AUTOSAR XML (schema 4-2-1)
package /ECUCompositionTypes
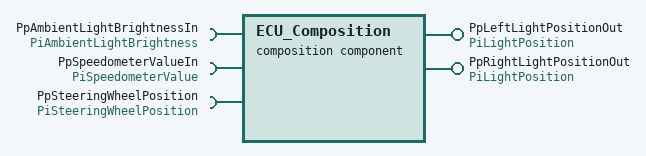
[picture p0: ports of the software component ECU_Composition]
  composition sw component type ECU_Composition
    provide port PpLeftLightPositionOut: provided-com-specs=[data-element=DeLightLength, {data-element=DeLightPosition, init-value=0}], provided-interface=PiLightPosition
    provide port PpRightLightPositionOut: provided-com-specs=[data-element=DeLightLength, {data-element=DeLightPosition, init-value=0}], provided-interface=PiLightPosition
    require port PpAmbientLightBrightnessIn: nonqueued-receiver-com-spec{data-element=DeAmbientLightBrightness, filter=data-filter-type=ALWAYS, init-value=constant-reference=CDarkLight}, required-interface=PiAmbientLightBrightness
    require port PpSpeedometerValueIn: nonqueued-receiver-com-spec{data-element=DeSpeedometerValue, filter=data-filter-type=ALWAYS, init-value=constant-reference=CInitSpeed}, required-interface=PiSpeedometerValue
    require port PpSteeringWheelPosition: nonqueued-receiver-com-spec{data-element=DeSteeringWheelPosition, filter=data-filter-type=ALWAYS, init-value=constant-reference=CSteeringWheelInitPosition}, required-interface=PiSteeringWheelPosition
    component CpCoApplication: type=CtCoApplication
    delegate CpCoApplication.PpAmbientLightBrightnessIn <-> outer port PpAmbientLightBrightnessIn
    delegate CpCoApplication.PpLeftLightPositionOut <-> outer port PpLeftLightPositionOut
    delegate CpCoApplication.PpRightLightPositionOut <-> outer port PpRightLightPositionOut
    delegate CpCoApplication.PpSpeedometerValueIn <-> outer port PpSpeedometerValueIn
    delegate CpCoApplication.PpSteeringWheelPosition <-> outer port PpSteeringWheelPosition
package /EndToEndProtections
  end to end protection set EndToEndConnections
package /VehicleProject
  system System: category=SYSTEM_EXTRACT
    system mapping System_MPPNG
      data-mappings:
        data-element=ECU_Composition.PpLeftLightPositionOut.DeLightPosition, system-signal=sig_LeftHAngle
        data-element=ECU_Composition.PpAmbientLightBrightnessIn.DeAmbientLightBrightness, system-signal=sig_AmbientLightBrightness
        data-element=ECU_Composition.PpSteeringWheelPosition.DeSteeringWheelPosition, system-signal=sig_SteeringWheelPosition
        data-element=ECU_Composition.PpLeftLightPositionOut.DeLightLength, system-signal=sig_LeftLightLength
        data-element=ECU_Composition.PpRightLightPositionOut.DeLightPosition, system-signal=sig_RightHAngle
        data-element=ECU_Composition.PpSpeedometerValueIn.DeSpeedometerValue, system-signal=sig_CurrentSpeedSlider
        data-element=ECU_Composition.PpRightLightPositionOut.DeLightLength, system-signal=sig_RightLightLength
    root-software-compositions:
      root sw composition prototype ECU_Composition: software-composition=ECU_Composition
